# R7FA8M1AH register map
Vendor: Renesas; Series: RA8; File version: 1.2
CPU: CM85 r0p0, little endian, MPU, FPU, VTOR, 4 interrupt priority bits
Registers are 32-bit, read-write, reset 0x0 unless marked. A register's access mark holds for its fields unless they carry their own. Offsets are from the block's base; [hi:lo] are bit positions; {n}, {i} and the like mark numbered series; 'fields as' and 'values as' point back to an identical list.

## CPSCU — CPU System Security Control Unit
Base 0x40008000
Same registers: CPSCU_NS 0x50008000
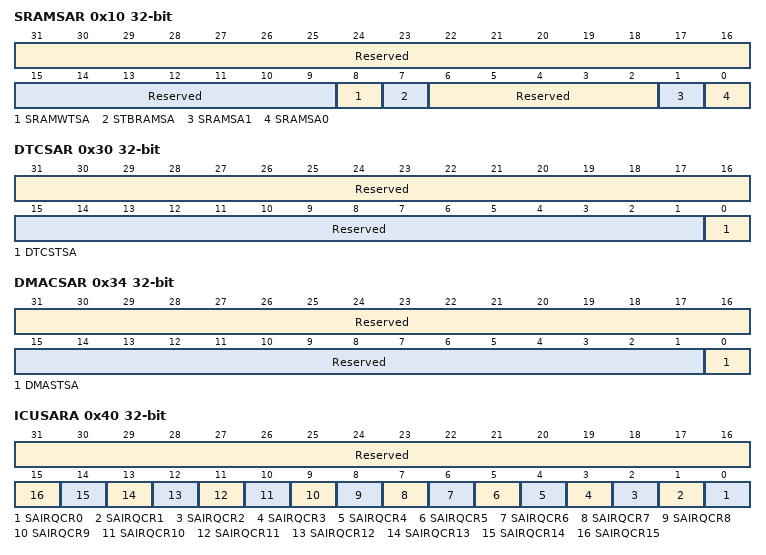
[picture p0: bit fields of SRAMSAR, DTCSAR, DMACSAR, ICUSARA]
0x10 SRAMSAR — SRAM Security Attribution Register
  [31:16] Reserved — These bits are read as 0000000000000000. The write value should be 0000000000000000.
  [15:9] Reserved — These bits are read as 0000000. The write value should be 0000000.
  [8] SRAMWTSA — Security attributes of registers for SRAMWTSC
    0=Secure; 1=Non-secure
  [7] STBRAMSA — Security attributes of registers for StandbySRAM
    0=Secure; 1=Non-secure
  [6:2] Reserved — These bits are read as 00000. The write value should be 00000.
  [1] SRAMSA1 — Security attributes of registers for SRAM1
    0=Secure; 1=Non-secure
  [0] SRAMSA0 — Security attributes of registers for SRAM0
    0=Secure; 1=Non-secure
0x30 DTCSAR — DTC Security Attribution Register
  [31:16] Reserved — These bits are read as 0000000000000000. The write value should be 0000000000000000.
  [15:1] Reserved — These bits are read as 000000000000000. The write value should be 000000000000000.
  [0] DTCSTSA — DTC Security Attribution
    0=Secure; 1=Non-secure
0x34 DMACSAR — DMAC Security Attribution Register
  [31:16] Reserved — These bits are read as 0000000000000000. The write value should be 0000000000000000.
  [15:1] Reserved — These bits are read as 000000000000000. The write value should be 000000000000000.
  [0] DMASTSA — DMAST Security Attribution
    0=Secure; 1=Non-secure
0x40 ICUSARA — ICU Security Attribution Register A
  [31:16] Reserved — These bits are read as 0000000000000000. The write value should be 0000000000000000.
  [n] SAIRQCR{n} (n=0..15) — Security attributes of registers for the IRQCR{n} register
    0=Secure; 1=Non-secure
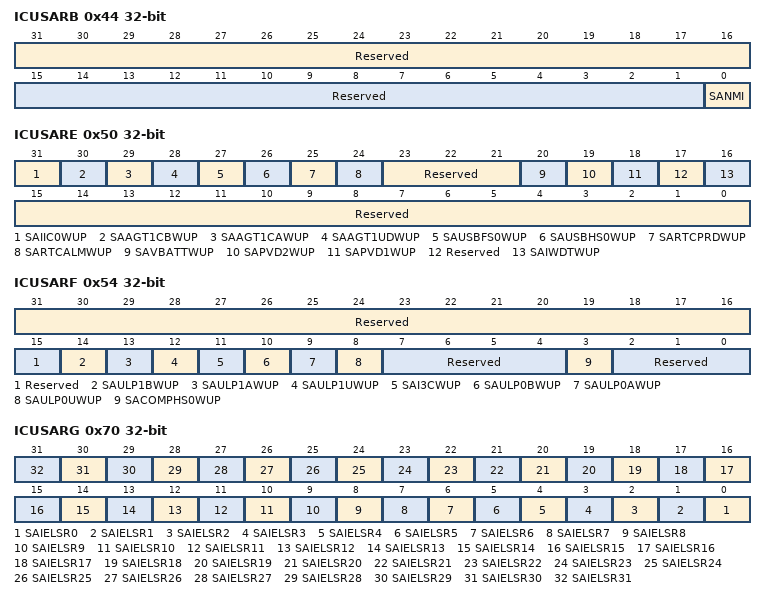
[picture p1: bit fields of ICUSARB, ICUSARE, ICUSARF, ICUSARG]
0x44 ICUSARB — ICU Security Attribution Register B
  [31:16] Reserved — These bits are read as 0000000000000000. The write value should be 0000000000000000.
  [15:1] Reserved — These bits are read as 000000000000000. The write value should be 000000000000000.
  [0] SANMI — Security attributes of registers for non-maskable interrupt
    0=Secure; 1=Non-secure
0x50 ICUSARE — ICU Security Attribution Register E
  [31] SAIIC0WUP — Security attributes of registers for WUPEN0.b31
    0=Secure; 1=Non-secure
  [30] SAAGT1CBWUP — Security attributes of registers for WUPEN0.b30
    0=Secure; 1=Non-secure
  [29] SAAGT1CAWUP — Security attributes of registers for WUPEN0.b29
    0=Secure; 1=Non-secure
  [28] SAAGT1UDWUP — Security attributes of registers for WUPEN0.b28
    0=Secure; 1=Non-secure
  [27] SAUSBFS0WUP — Security attributes of registers for WUPEN0.b27
    0=Secure; 1=Non-secure
  [26] SAUSBHS0WUP — Security attributes of registers for WUPEN0.b26
    0=Secure; 1=Non-secure
  [25] SARTCPRDWUP — Security attributes of registers for WUPEN0.b25
    0=Secure; 1=Non-secure
  [24] SARTCALMWUP — Security attributes of registers for WUPEN0.b24
    0=Secure; 1=Non-secure
  [23:21] Reserved — These bits are read as 000. The write value should be 000.
  [20] SAVBATTWUP — Security attributes of registers for WUPEN0.b20
    0=Secure; 1=Non-secure
  [19] SAPVD2WUP — Security attributes of registers for WUPEN0.b19
    0=Secure; 1=Non-secure
  [18] SAPVD1WUP — Security attributes of registers for WUPEN0.b18
    0=Secure; 1=Non-secure
  [17] Reserved — This bit is read as 0. The write value should be 0.
  [16] SAIWDTWUP — Security attributes of registers for WUPEN0.b16
    0=Secure; 1=Non-secure
  [15:0] Reserved — These bits are read as 0000000000000000. The write value should be 0000000000000000.
0x54 ICUSARF — ICU Security Attribution Register F
  [31:16] Reserved — These bits are read as 0000000000000000. The write value should be 0000000000000000.
  [15] Reserved — This bit is read as 0. The write value should be 0.
  [14] SAULP1BWUP — Security attributes of registers for WUPEN1.b14
    0=Secure; 1=Non-secure
  [13] SAULP1AWUP — Security attributes of registers for WUPEN1.b13
    0=Secure; 1=Non-secure
  [12] SAULP1UWUP — Security attributes of registers for WUPEN1.b12
    0=Secure; 1=Non-secure
  [11] SAI3CWUP — Security attributes of registers for WUPEN1.b11
    0=Secure; 1=Non-secure
  [10] SAULP0BWUP — Security attributes of registers for WUPEN1.b10
    0=Secure; 1=Non-secure
  [9] SAULP0AWUP — Security attributes of registers for WUPEN1.b9
    0=Secure; 1=Non-secure
  [8] SAULP0UWUP — Security attributes of registers for WUPEN1.b8
    0=Secure; 1=Non-secure
  [7:4] Reserved — These bits are read as 0000. The write value should be 0000.
  [3] SACOMPHS0WUP — Security attributes of registers for WUPEN1.b3
    0=Secure; 1=Non-secure
  [2:0] Reserved — These bits are read as 000. The write value should be 000.
0x70 ICUSARG — ICU Security Attribution Register G
  [all] fields
    0=Secure; 1=Non-secure
  [n] SAIELSR{n} (n=0..31) — Security attributes of registers for IELSR{n}
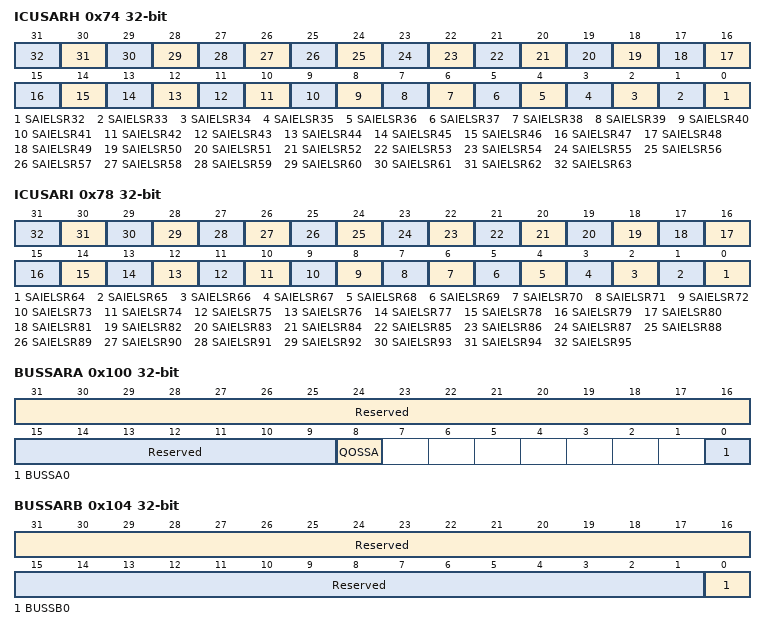
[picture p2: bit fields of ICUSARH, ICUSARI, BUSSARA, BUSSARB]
0x74 ICUSARH — ICU Security Attribution Register H
  [all] fields
    0=Secure; 1=Non-secure
  [n-32] SAIELSR{n} (n=32..63) — Security attributes of registers for IELSR{n}
0x78 ICUSARI — ICU Security Attribution Register I
  [all] fields
    0=Secure; 1=Non-secure
  [n-64] SAIELSR{n} (n=64..95) — Security attributes of registers for IELSR{n}
0x100 BUSSARA — BUS Security Attribution Register A
  [31:16] Reserved — These bits are read as 0000000000000000. The write value should be 0000000000000000.
  [15:9] Reserved — These bits are read as 0000000. The write value should be 0000000.
  [8] QOSSA — Security attributes of registers for QOS register
    0=Secure; 1=Non-secure
  [0] BUSSA0 — BUS Security attributes A0.
    0=Secure; 1=Non-secure
0x104 BUSSARB — BUS Security Attribution Register B
  [31:16] Reserved — These bits are read as 0000000000000000. The write value should be 0000000000000000.
  [15:1] Reserved — These bits are read as 000000000000000. The write value should be 000000000000000.
  [0] BUSSB0 — BUS Security attributes B0.
    0=Secure; 1=Non-secure
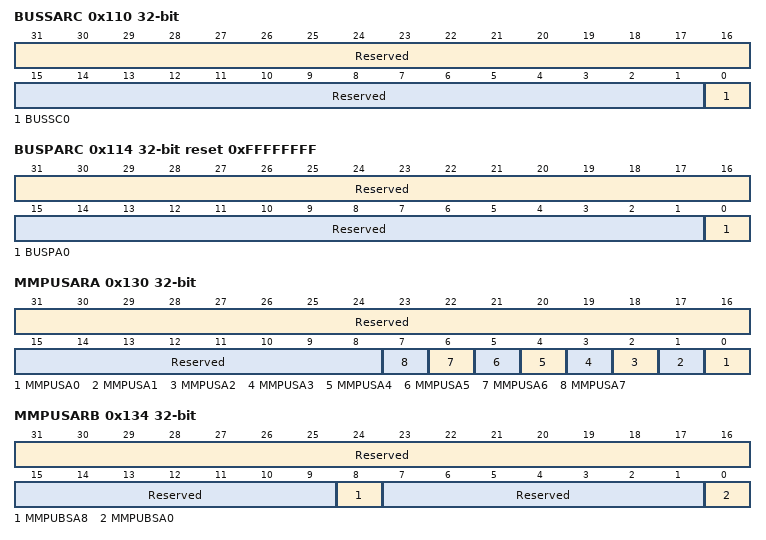
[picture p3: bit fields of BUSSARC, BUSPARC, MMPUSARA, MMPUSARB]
0x110 BUSSARC — BUS Security Attribution Register C (External BUS)
  [31:16] Reserved — These bits are read as 0000000000000000. The write value should be 0000000000000000.
  [15:1] Reserved — These bits are read as 000000000000000. The write value should be 000000000000000.
  [0] BUSSC0 — External BUS Security attributes.
    0=Secure; 1=Non-secure
0x114 BUSPARC reset 0xFFFFFFFF — BUS Privileged Attribution Register C (External BUS)
  [31:16] Reserved — These bits are read as 1111111111111111. The write value should be 1111111111111111.
  [15:1] Reserved — These bits are read as 111111111111111. The write value should be 111111111111111.
  [0] BUSPA0 — External BUS Privileged attributes.
    0=privileged; 1=unprivileged
0x130 MMPUSARA — Master MPU Security Attribution Register A
  [31:16] Reserved — These bits are read as 0000000000000000. The write value should be 0000000000000000.
  [15:8] Reserved — These bits are read as 00000000. The write value should be 00000000.
  [n] MMPUSA{n} (n=0..7) — MMPUA Security attributes{n}
    0=Secure; 1=Non-secure
0x134 MMPUSARB — Master MPU Security Attribution Register B
  [31:16] Reserved — These bits are read as 0000000000000000. The write value should be 0000000000000000.
  [15:9] Reserved — These bits are read as 0000000. The write value should be 0000000.
  [8] MMPUBSA8 — MMPUB8 Security attributes.
    0=Secure; 1=Non-secure
  [7:1] Reserved — These bits are read as 0000000. The write value should be 0000000.
  [0] MMPUBSA0 — MMPUB0 Security attributes.
    0=Secure; 1=Non-secure
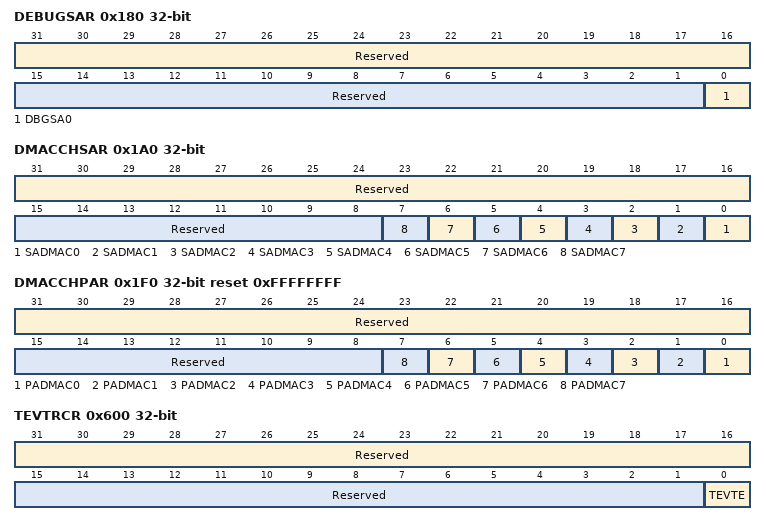
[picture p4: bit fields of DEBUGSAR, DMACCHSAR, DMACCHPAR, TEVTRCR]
0x180 DEBUGSAR — Debug Security Attribution Register
  [31:16] Reserved — These bits are read as 0000000000000000. The write value should be 0000000000000000.
  [15:1] Reserved — These bits are read as 000000000000000. The write value should be 000000000000000.
  [0] DBGSA0 — Security attributes of registers for the DEBUG register
    0=Secure; 1=Non-secure
0x1A0 DMACCHSAR — DMAC channel Security Attribution Register
  [31:16] Reserved — These bits are read as 0000000000000000. The write value should be 0000000000000000.
  [15:8] Reserved — These bits are read as 00000000. The write value should be 00000000.
  [n] SADMAC{n} (n=0..7) — Security attributes of registers for DMAC channel {n}
    0=Secure; 1=Non-secure
0x1F0 DMACCHPAR reset 0xFFFFFFFF — DMAC channel Privileged Attribution Register
  [31:16] Reserved — These bits are read as 1111111111111111. The write value should be 1111111111111111.
  [15:8] Reserved — These bits are read as 11111111. The write value should be 11111111.
  [n] PADMAC{n} (n=0..7) — Privileged attributes of registers for DMAC channel {n}
    0=privileged; 1=unprivileged
{0x400+4i} SRAMSABAR{i} (i=0..1) reset 0x1FE000 — SRAM Security Attribute Boundary Address Register {i}
  [31:0] Reserved — These bits are read as 00000000000111111110000000000000. The write value should be 00000000000111111110000000000000.
0x420 STBRAMSABAR reset 0x7F80 — Standby SRAM Security Attribute Boundary Address Register
  [31:0] Reserved — These bits are read as 00000000000000000111111110000000. The write value should be 00000000000000000111111110000000.
0x490 STBRAMPABAR_NS — Standby SRAM Privileged Attribute Boundary Address Register for Non-Secure region
  [31:0] Reserved — These bits are read as 00000000000000000000000000000000. The write value should be 00000000000000000000000000000000.
0x494 STBRAMPABAR_S — Standby SRAM Privileged Attribute Boundary Address Register for Secure region
  fields as STBRAMPABAR_NS
0x600 TEVTRCR — Trusted EVenT Route Control Register
  [31:16] Reserved — These bits are read as 0000000000000000. The write value should be 0000000000000000.
  [15:1] Reserved — These bits are read as 000000000000000. The write value should be 000000000000000.
  [0] TEVTE — Trusted Event Route Control
    0=Disable; 1=Enable
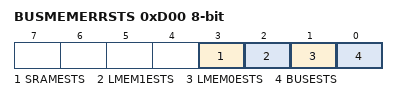
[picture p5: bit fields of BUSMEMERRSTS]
0xD00 BUSMEMERRSTS 8-bit ro (reset mask 0xFE) — BUS Memory Error Status Register
  [all] fields
    0=No error occurred; 1=Error occurred
  [3] SRAMESTS — SRAM Error STatuS
  [2] LMEM1ESTS — Local_MEMory1 Error STatuS
  [1] LMEM0ESTS — Local_MEMory0 Error STatuS
  [0] BUSESTS — BUS Error STatuS
